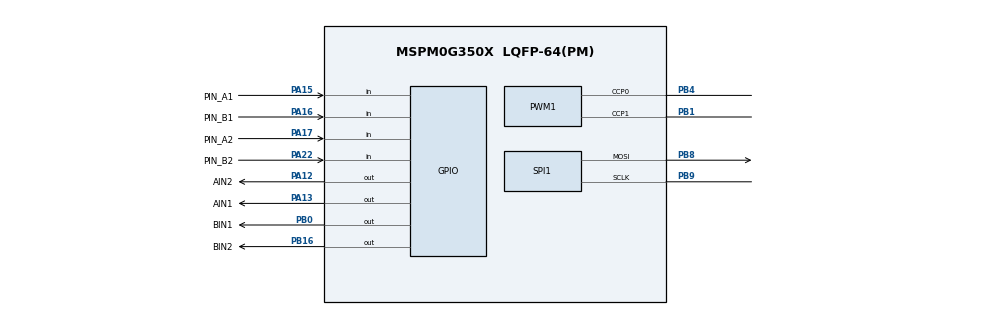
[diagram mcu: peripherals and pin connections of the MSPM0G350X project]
/**
 * @cliArgs --device "MSPM0G350X" --part "Default" --package "LQFP-64(PM)" --product "mspm0_sdk@2.02.00.05"
 * @versions {"tool":"1.21.1+3772"}
 */

/**
 * Import the modules used in this configuration.
 */
const GPIO   = scripting.addModule("/ti/driverlib/GPIO", {}, false);
const GPIO1  = GPIO.addInstance();
const GPIO2  = GPIO.addInstance();
const GPIO3  = GPIO.addInstance();
const PWM    = scripting.addModule("/ti/driverlib/PWM", {}, false);
const PWM1   = PWM.addInstance();
const SPI    = scripting.addModule("/ti/driverlib/SPI", {}, false);
const SPI1   = SPI.addInstance();
const SYSCTL = scripting.addModule("/ti/driverlib/SYSCTL");
const TIMER  = scripting.addModule("/ti/driverlib/TIMER", {}, false);
const TIMER1 = TIMER.addInstance();

/**
 * Write custom configuration values to the imported modules.
 */
const divider9       = system.clockTree["UDIV"];
divider9.divideValue = 2;

const multiplier2         = system.clockTree["PLL_QDIV"];
multiplier2.multiplyValue = 4;

const mux4       = system.clockTree["EXHFMUX"];
mux4.inputSelect = "EXHFMUX_XTAL";

const mux8       = system.clockTree["HSCLKMUX"];
mux8.inputSelect = "HSCLKMUX_SYSPLL0";

const mux12       = system.clockTree["SYSPLLMUX"];
mux12.inputSelect = "zSYSPLLMUX_HFCLK";

const pinFunction4        = system.clockTree["HFXT"];
pinFunction4.inputFreq    = 40;
pinFunction4.enable       = true;
pinFunction4.HFXTStartup  = 10;
pinFunction4.HFCLKMonitor = true;

GPIO1.$name                          = "motor";
GPIO1.associatedPins.create(4);
GPIO1.associatedPins[0].$name        = "AIN1";
GPIO1.associatedPins[0].assignedPin  = "13";
GPIO1.associatedPins[0].assignedPort = "PORTA";
GPIO1.associatedPins[0].pin.$assign  = "PA13";
GPIO1.associatedPins[1].$name        = "AIN2";
GPIO1.associatedPins[1].assignedPin  = "12";
GPIO1.associatedPins[1].assignedPort = "PORTA";
GPIO1.associatedPins[1].pin.$assign  = "PA12";
GPIO1.associatedPins[2].$name        = "BIN1";
GPIO1.associatedPins[2].assignedPin  = "0";
GPIO1.associatedPins[2].assignedPort = "PORTB";
GPIO1.associatedPins[2].pin.$assign  = "PB0";
GPIO1.associatedPins[3].$name        = "BIN2";
GPIO1.associatedPins[3].assignedPin  = "16";
GPIO1.associatedPins[3].assignedPort = "PORTB";
GPIO1.associatedPins[3].pin.$assign  = "PB16";

const Board = scripting.addModule("/ti/driverlib/Board", {}, false);

GPIO2.$name                          = "GPIO_LCD";
GPIO2.associatedPins.create(4);
GPIO2.associatedPins[0].$name        = "PIN_RES";
GPIO2.associatedPins[0].assignedPort = "PORTB";
GPIO2.associatedPins[0].assignedPin  = "10";
GPIO2.associatedPins[1].$name        = "PIN_DC";
GPIO2.associatedPins[1].assignedPort = "PORTB";
GPIO2.associatedPins[1].assignedPin  = "11";
GPIO2.associatedPins[2].$name        = "PIN_CS";
GPIO2.associatedPins[2].assignedPort = "PORTB";
GPIO2.associatedPins[2].assignedPin  = "14";
GPIO2.associatedPins[3].$name        = "PIN_BLK";
GPIO2.associatedPins[3].assignedPort = "PORTB";
GPIO2.associatedPins[3].assignedPin  = "26";

GPIO3.$name                               = "GPIO_ENCODER";
GPIO3.port                                = "PORTA";
GPIO3.associatedPins.create(4);
GPIO3.associatedPins[0].$name             = "PIN_A1";
GPIO3.associatedPins[0].direction         = "INPUT";
GPIO3.associatedPins[0].assignedPin       = "15";
GPIO3.associatedPins[0].interruptPriority = "0";
GPIO3.associatedPins[0].polarity          = "RISE";
GPIO3.associatedPins[0].interruptEn       = true;
GPIO3.associatedPins[0].pin.$assign       = "PA15";
GPIO3.associatedPins[1].$name             = "PIN_B1";
GPIO3.associatedPins[1].direction         = "INPUT";
GPIO3.associatedPins[1].assignedPin       = "16";
GPIO3.associatedPins[1].interruptPriority = "0";
GPIO3.associatedPins[1].polarity          = "RISE";
GPIO3.associatedPins[1].pin.$assign       = "PA16";
GPIO3.associatedPins[2].$name             = "PIN_A2";
GPIO3.associatedPins[2].direction         = "INPUT";
GPIO3.associatedPins[2].assignedPin       = "17";
GPIO3.associatedPins[2].interruptEn       = true;
GPIO3.associatedPins[2].interruptPriority = "0";
GPIO3.associatedPins[2].polarity          = "RISE";
GPIO3.associatedPins[2].pin.$assign       = "PA17";
GPIO3.associatedPins[3].$name             = "PIN_B2";
GPIO3.associatedPins[3].direction         = "INPUT";
GPIO3.associatedPins[3].assignedPin       = "22";
GPIO3.associatedPins[3].interruptPriority = "0";
GPIO3.associatedPins[3].polarity          = "RISE";
GPIO3.associatedPins[3].pin.$assign       = "PA22";

PWM1.$name                              = "PWM_MOTOR";
PWM1.timerCount                         = 10000;
PWM1.timerStartTimer                    = true;
PWM1.peripheral.$assign                 = "TIMA1";
PWM1.peripheral.ccp0Pin.$assign         = "PB4";
PWM1.peripheral.ccp1Pin.$assign         = "PB1";
PWM1.PWM_CHANNEL_0.$name                = "ti_driverlib_pwm_PWMTimerCC0";
PWM1.PWM_CHANNEL_1.$name                = "ti_driverlib_pwm_PWMTimerCC1";
PWM1.ccp0PinConfig.$name                = "ti_driverlib_gpio_GPIOPinGeneric0";
PWM1.ccp0PinConfig.direction            = scripting.forceWrite("OUTPUT");
PWM1.ccp0PinConfig.hideOutputInversion  = scripting.forceWrite(false);
PWM1.ccp0PinConfig.onlyInternalResistor = scripting.forceWrite(false);
PWM1.ccp0PinConfig.passedPeripheralType = scripting.forceWrite("Digital");
PWM1.ccp1PinConfig.$name                = "ti_driverlib_gpio_GPIOPinGeneric1";
PWM1.ccp1PinConfig.direction            = scripting.forceWrite("OUTPUT");
PWM1.ccp1PinConfig.hideOutputInversion  = scripting.forceWrite(false);
PWM1.ccp1PinConfig.onlyInternalResistor = scripting.forceWrite(false);
PWM1.ccp1PinConfig.passedPeripheralType = scripting.forceWrite("Digital");

SPI1.$name                              = "SPI_LCD";
SPI1.targetBitRate                      = 32000000;
SPI1.frameFormat                        = "MOTO3";
SPI1.direction                          = "PICO";
SPI1.peripheral.$assign                 = "SPI1";
SPI1.peripheral.sclkPin.$assign         = "PB9";
SPI1.peripheral.mosiPin.$assign         = "PB8";
SPI1.sclkPinConfig.$name                = "ti_driverlib_gpio_GPIOPinGeneric2";
SPI1.sclkPinConfig.direction            = scripting.forceWrite("OUTPUT");
SPI1.sclkPinConfig.onlyInternalResistor = scripting.forceWrite(false);
SPI1.sclkPinConfig.passedPeripheralType = scripting.forceWrite("Digital");
SPI1.mosiPinConfig.$name                = "ti_driverlib_gpio_GPIOPinGeneric3";
SPI1.mosiPinConfig.direction            = scripting.forceWrite("OUTPUT");
SPI1.mosiPinConfig.hideOutputInversion  = scripting.forceWrite(false);
SPI1.mosiPinConfig.onlyInternalResistor = scripting.forceWrite(false);
SPI1.mosiPinConfig.passedPeripheralType = scripting.forceWrite("Digital");

SYSCTL.forceDefaultClkConfig = true;
SYSCTL.clockTreeEn           = true;

TIMER1.$name             = "TIMER_TICK";
TIMER1.timerClkDiv       = 8;
TIMER1.timerClkPrescale  = 10;
TIMER1.timerMode         = "PERIODIC";
TIMER1.timerPeriod       = "20 ms";
TIMER1.timerStartTimer   = true;
TIMER1.interrupts        = ["ZERO"];
TIMER1.interruptPriority = "3";

/**
 * Pinmux solution for unlocked pins/peripherals. This ensures that minor changes to the automatic solver in a future
 * version of the tool will not impact the pinmux you originally saw.  These lines can be completely deleted in order to
 * re-solve from scratch.
 */
pinFunction4.peripheral.$suggestSolution           = "SYSCTL";
pinFunction4.peripheral.hfxInPin.$suggestSolution  = "PA5";
pinFunction4.peripheral.hfxOutPin.$suggestSolution = "PA6";
Board.peripheral.$suggestSolution                  = "DEBUGSS";
Board.peripheral.swclkPin.$suggestSolution         = "PA20";
Board.peripheral.swdioPin.$suggestSolution         = "PA19";
GPIO2.associatedPins[0].pin.$suggestSolution       = "PB10";
GPIO2.associatedPins[1].pin.$suggestSolution       = "PB11";
GPIO2.associatedPins[2].pin.$suggestSolution       = "PB14";
GPIO2.associatedPins[3].pin.$suggestSolution       = "PB26";
TIMER1.peripheral.$suggestSolution                 = "TIMA0";
